# SC32F10T_10G register map
File version: 1.0
CPU: CM0+ r0p1, little endian, MPU, no FPU, 4 interrupt priority bits
Registers are 32-bit, access not given, reset 0x0 unless marked. A register's access mark holds for its fields unless they carry their own. Offsets are from the block's base; [hi:lo] are bit positions; {n}, {i} and the like mark numbered series.

## BTM
Base 0x40022100
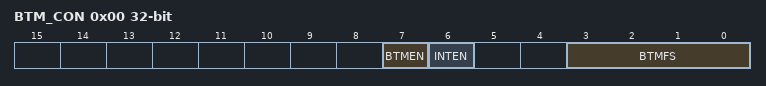
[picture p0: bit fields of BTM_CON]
0x00 BTM_CON rw — 低频定时器控制寄存器
  [7] BTMEN — Base Timer启动控制位 0：Base Timer不启动 1：Base Timer启动
  [6] INTEN — 中断请求 CPU的使能控制位 0：禁止中断请求 1：使能中断请求
  [3:0] BTMFS — 低频时钟中断频率选择 0000：每15.625ms产生一个中断 0001：每31.25ms产生一个中断 0010：每62.5ms产生一个中断 0011：每125ms产生一个中断 0100：每0.25 s产生一个中断 0101：每0.5 s产生一个中断 0110：每1.0 s产生一个中断 0111：每2.0 s产生一个中断 1000：每4.0 s产生一个中断 1001：每8.0 s产生一个中断 10
0x04 BTM_STS rw — BTM标志位寄存器
  [0] BTMIF — Base Timer中断标志位该位由硬件置1，通过软件写1清0。BTM计数满足BTMFS设置条件时该位自动置起。

## ADC
Base 0x40022110
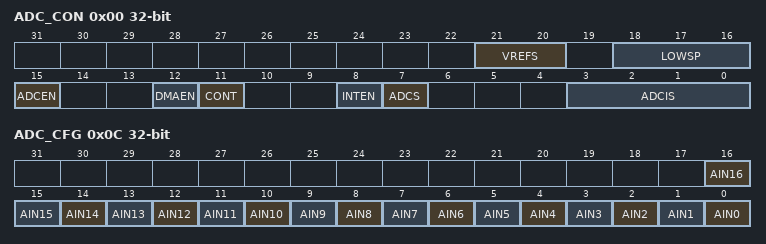
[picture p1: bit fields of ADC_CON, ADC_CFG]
0x00 ADC_CON rw — ADC控制寄存器
  [21:20] VREFS — 参考电压选择控制位00：选择ADC的VREF为VDD； 01：选择ADC的VREF为内部准确的2.048V； 10：选择ADC的VREF为内部准确的1.024V； 11：选择ADC的VREF为内部准确的2.4V；
  [18:16] LOWSP — ADC 采样周期数选择控制位 100：采样时间为3个系统时钟，（约 100ns @ fPCLK2 = 32MHz） 101：采样时间约6个系统时钟，（约 200ns @ fPCLK2 = 32MHz） 110：采样时间约 16个系统时钟，（约 500ns @ fPCLK2 = 32MHz） 111：采样时间约 32个系统时钟，（约 1000ns @ fPCLK2 = 32MHz） 其它：保留 说明
  [15] ADCEN — ADC模块电源启动控制位 0：关闭ADC模块电源 1：开启ADC 模块电源
  [12] DMAEN — DMA请求使能控制位 该位用于使能 DMA 请求的生成。写1后可使用 DMA 控制器自动管理ADC转换的数据。 0：禁止 DMA请求 1：使能 DMA请求 注意：通过软件对此位执行写操作时，应确保当前未进行任何转换。
  [11] CONT — 单次/连续转换模式选择位该位由软件置 1 和清0。该位置 1 时，转换将持续进行，直到该位清0。 0：单次转换模式 1：连续转换模式
  [8] INTEN — 中断请求 CPU的使能控制位 0：禁止中断请求 1：使能中断请求
  [7] ADCS — ADC转换触发控制位该位是ADC转换的触发信号，由软件置 1 ，由硬件清0。对此位写 1 会触发一次 ADC 的转换。 注意：对ADCS置1之后，到中断标志ADCIF置起前不要对ADC_CON寄存器进行写操作。
  [3:0] ADCIS — ADC 输入通道选择位 00000：选择 AIN0 为 ADC 的输入 00001：选择AIN1 为 ADC 的输入 00111：选择 AIN7为 ADC 的输入 01000：选择 AIN8为 ADC 的输入 01001：选择AIN9 为 ADC 的输入 01010：选择AIN10 为 ADC 的输入 01011：选择AIN11 为 ADC 的输入 01100：选择AIN12 为 ADC 的输入
0x04 ADC_STS rw — ADC标志状态位寄存器
  [0] EOC
0x08 ADC_VALUE
0x0C ADC_CFG rw — ADC端口设置寄存器
  [n] AIN{n} (n=0..16)

## CMP
Base 0x40022130
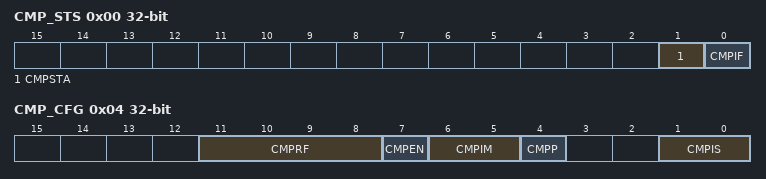
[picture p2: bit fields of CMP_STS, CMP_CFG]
0x00 CMP_STS rw — 模拟比较器状态寄存器
  [1] CMPSTA — 模拟比较器输出状态位0：比较器正端电压小于负端电压1：比较器正端电压大于负端电压
  [0] CMPIF — 模拟比较器中断标志位该位由硬件置1，通过软件写1清0。0：比较器中断未被触发；1：当比较器满足中断触发条件时，此位会被硬件置 1。如果此时 CMPIM[1:0]不为00, 比较器中断产生。
0x04 CMP_CFG rw — 模拟比较器配置寄存器
  [11:8] CMPRF — 模拟比较器负端比较电压选择位模拟比较器负端比较电压设置项如下：0000： CMPR；0001： 1/16VDD 0010： 2/16VDD 0011： 3/16VDD 0100： 4/16VDD 0101： 5/16VDD 0110： 6/16VDD 0111： 7/16VDD 1000： 8/16VDD 1001： 9/16VDD 1010： 10/16VDD 1011： 11/16VDD 11
  [7] CMPEN — 模拟比较器使能位0：关闭模拟比较器1：使能模拟比较器
  [6:5] CMPIM — 模拟比较器中断模式选择位00：不产生中断01：上升沿中断：IN+从小于 IN- 到大于 IN- 后会产生中断；10：下降沿中断：IN+从大于 IN- 到小于 IN- 后会产生中断；11：双沿中断：IN+从小于 IN- 到大于 IN- ，或IN+从大于 IN- 到小于 IN-后均会产生中断；
  [4] CMPP — 模拟比较器正端输入选择：0：模拟比较器正端的输入为CMP0~3之一为，由CMPIS[1:0]设定1：模拟比较器正端的输入为内部1.5V基准电压
  [1:0] CMPIS — 模拟比较器正端输入通道选择位CMPP为1时，该位无效：00：选用 CMP0 为模拟比较器正端的输入；01：选用 CMP1 为模拟比较器正端的输入；10：选用 CMP2 为模拟比较器正端的输入；11：选用 CMP3 为模拟比较器正端的输入；

## FPGA — FPGA peripheral (PGA_TypeDef)
Base 0x40022140
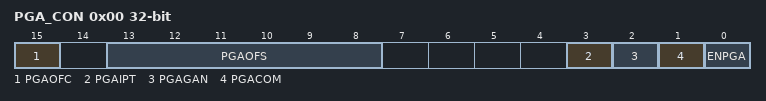
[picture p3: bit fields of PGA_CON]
0x00 PGA_CON rw — CMP Control register
  [15] PGAOFC, [13:8] PGAOFS, [3] PGAIPT, [2] PGAGAN, [1] PGACOM, [0] ENPGA

## TK — TK peripheral (TK_TypeDef)
Base 0x40022200
0x00 TK_CHN — TK Channel register
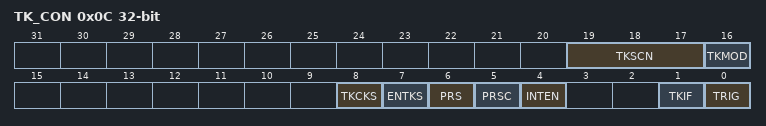
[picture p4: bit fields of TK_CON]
0x0C TK_CON rw — TK Control register
  [19:17] TKSCN, [16] TKMOD, [8] TKCKS, [7] ENTKS, [6] PRS, [5] PRSC, [4] INTEN, [1] TKIF, [0] TRIG
0x10 TK_CFG — TK Config register
0x18 TK_CNT — TK RawData register
0x1C TK_TM

## LCD_LED — LCD_LED peripheral (LCD_LED_TypeDef)
Base 0x40022280
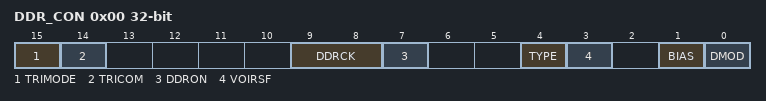
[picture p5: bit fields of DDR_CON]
0x00 DDR_CON rw — Display Drive Control register
  [15] TRIMODE, [14] TRICOM, [9:8] DDRCK, [7] DDRON, [4] TYPE, [3] VOIRSF, [1] BIAS, [0] DMOD
0x04 DDR_CFG rw — Display Drive Config register
  [11:8] VLCD, [8:7] SCS, [5:4] DUTY, [1:0] DMOD
0x08 SEG_EN — Segment IO Enable register
0x10 COM_EN — COM IO Enable register register

## EXTI — EXTI peripheral (EXTI_TypeDef)
Base 0x40011300
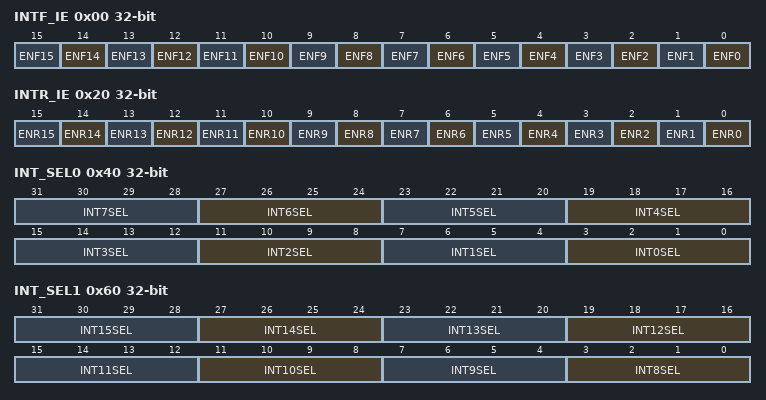
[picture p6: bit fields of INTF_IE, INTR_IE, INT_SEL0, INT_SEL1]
0x00 INTF_IE rw — EXTI Fall edge Enable register
  [n] ENF{n} (n=0..15)
0x20 INTR_IE rw — EXTI Rise edge Enable register register
  [n] ENR{n} (n=0..15)
0x40 INT_SEL0 rw — EXTI0-7 Port Select register
  [4n+3:4n] INT{n}SEL (n=0..7)
0x60 INT_SEL1 rw — EXTI8-15 Port Select register
  [4n-29:4n-32] INT{n}SEL (n=8..15)
0x80 INTF_CON — EXTI Fall Control register
0xA0 INTR_CON rw — EXTI Rise Control register
  [n] FT{n} (n=2..15), [n] RT{n} (n=2..15), [0] FT0, [0] RT0
0xC0 INTF_STS rw — EXTI Fall Status register
  [n] FIF{n} (n=2..15), [n] RIF{n} (n=2..15), [0] FIF0, [0] RIF0
0xE0 INTR_STS — EXTI Rise status register
